# NANO103AE_v1 register map
File version: 1.0
Registers are 32-bit, read-write, reset 0x0 unless marked. A register's access mark holds for its fields unless they carry their own. Offsets are from the block's base; [hi:lo] are bit positions; {n}, {i} and the like mark numbered series.

## RTC — RTC Register Map
Base 0x40008000
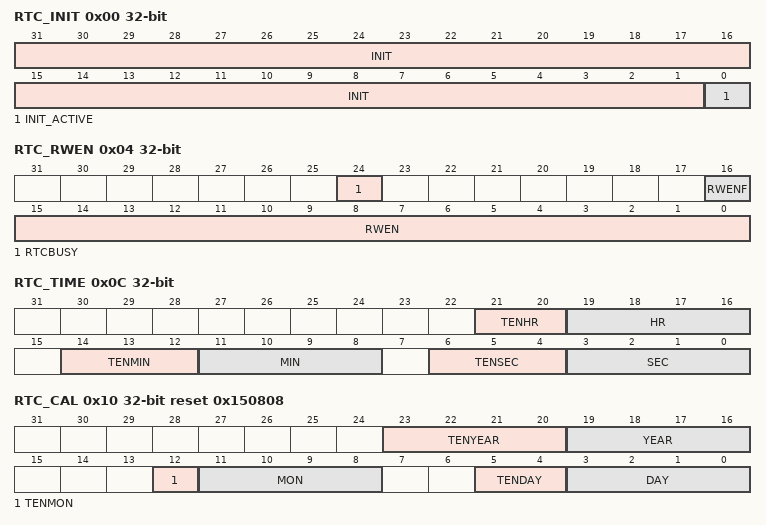
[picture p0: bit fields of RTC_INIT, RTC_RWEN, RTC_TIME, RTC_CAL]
0x00 RTC_INIT — RTC Initiation Register
  [31:1] INIT — RTC Initiation. When RTC block is powered on, RTC is at reset state. User has to write a number (0x a5eb1357) to INIT to make RTC leaving reset state. Once the INIT is written as 0xa5eb1357, the RTC will be in un-reset state permanently. The INIT is a write-only field and read value will be always 0.
  [0] INIT_ACTIVE ro — RTC Active Status (Read Only)
    0=RTC is at reset state; 1=RTC is at normal active state
0x04 RTC_RWEN — RTC Access Enable Register
  [24] RTCBUSY — RTC Write Busy Flag. 0: RTC write access enable. 1: RTC write access disable , RTC under Busy Status. Note: BUSY By Exceed RTC IP Prcessing Write Counter Capacity ( 6 counts Per 1120 PCLK cycles) .
  [16] RWENF ro — RTC Register Access Enable Flag (Read Only)
    0=RTC register read/write Disabled; 1=RTC register read/write Enabled
  [15:0] RWEN wo — RTC Register Access Enable Password (Write Only). Writing 0xA965 to this register will enable RTC access and keep 1024 RTC clock. Writing other vaule will clear RWENF.
0x08 RTC_FREQADJ reset 0x200000 — RTC Frequency Compensation Register
  [21:0] FREQADJ — Frequence Compensation Register. LXT period: the clock period (Hz) of LXT.
0x0C RTC_TIME — RTC Time Loading Register
  [21:20] TENHR — 10-hour Time Digit (0~2). When RTC runs as 12-hour time scale mode, RTC_TIME[21] (the high bit of TENHR[1:0]) means AM/PM indication. (If RTC_TIME[21] is 1, it indicates PM time message.) the high bit of TENHR (RTC_TIME[21]) means AM/PM indication.
  [19:16] HR — 1-Hour Time Digit (0~9)
  [14:12] TENMIN — 10-Min Time Digit (0~5)
  [11:8] MIN — 1-Min Time Digit (0~9)
  [6:4] TENSEC — 10-Sec Time Digit (0~5)
  [3:0] SEC — 1-Sec Time Digit (0~9)
0x10 RTC_CAL reset 0x150808 — RTC Calendar Loading Register
  [23:20] TENYEAR — 10-Year Calendar Digit (0~9)
  [19:16] YEAR — 1-Year Calendar Digit (0~9)
  [12] TENMON — 10-Month Calendar Digit (0~1)
  [11:8] MON — 1-Month Calendar Digit (0~9)
  [5:4] TENDAY — 10-Day Calendar Digit (0~3)
  [3:0] DAY — 1-Day Calendar Digit (0~9)
0x14 RTC_CLKFMT reset 0x1 — RTC Time Scale Selection Register
  [0] _24HEN — 24-hour /12-hour Time Scale Selection. Indicates that RTC_TIME and RTC_TALM are in 24-hour time scale or 12-hour time scale
    0=12-hour time scale with AM and PM indication selected; 1=24-hour time scale selected
0x18 RTC_WEEKDAY reset 0x6 — RTC Day of the Week Register
  [2:0] WEEKDAY — Day of the Week Register
    0=Sunday; 1=Monday; 2=Tuesday; 3=Wednesday; 4=Thursday; 5=Friday; 6=Saturday
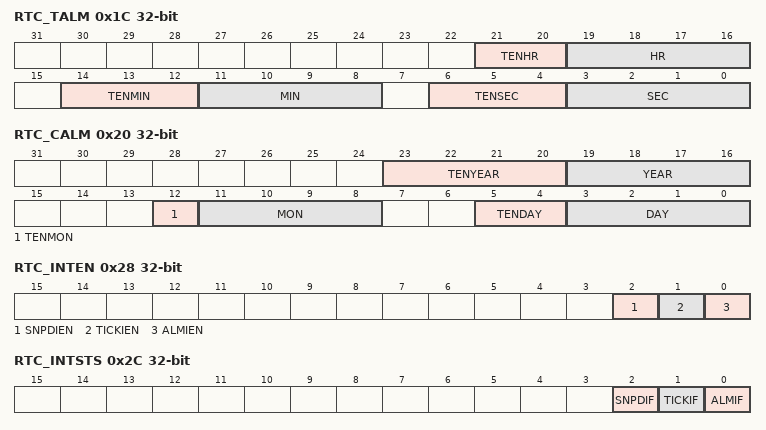
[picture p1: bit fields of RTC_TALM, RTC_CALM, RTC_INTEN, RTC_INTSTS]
0x1C RTC_TALM — RTC Time Alarm Register
  [21:20] TENHR — 10-hour Time Digit of Alarm Setting (0~2). When RTC runs as 12-hour time scale mode, RTC_TIME[21] (the high bit of TENHR[1:0]) means AM/PM indication. (If RTC_TIME[21] is 1, it indicates PM time message.)the high bit of TENHR (RTC_TIME[21]) means AM/PM indication.
  [19:16] HR — 1-Hour Time Digit of Alarm Setting (0~9)
  [14:12] TENMIN — 10-Min Time Digit of Alarm Setting (0~5)
  [11:8] MIN — 1-Min Time Digit of Alarm Setting (0~9)
  [6:4] TENSEC — 10-Sec Time Digit of Alarm Setting (0~5)
  [3:0] SEC — 1-Sec Time Digit of Alarm Setting (0~9)
0x20 RTC_CALM — RTC Calendar Alarm Register
  [23:20] TENYEAR — 10-Year Calendar Digit of Alarm Setting (0~9)
  [19:16] YEAR — 1-Year Calendar Digit of Alarm Setting (0~9)
  [12] TENMON — 10-Month Calendar Digit of Alarm Setting (0~1)
  [11:8] MON — 1-Month Calendar Digit of Alarm Setting (0~9)
  [5:4] TENDAY — 10-Day Calendar Digit of Alarm Setting (0~3)
  [3:0] DAY — 1-Day Calendar Digit of Alarm Setting (0~9)
0x24 RTC_LEAPYEAR ro — RTC Leap Year Indicator Register
  [0] LEAPYEAR — Leap Year Indication Register (Read Only)
    0=This year is not a leap year; 1=This year is leap year
0x28 RTC_INTEN — RTC Interrupt Enable Register
  [2] SNPDIEN — Snoop Detection Interrupt Enable Bit
    0=Snoop detectedinterrupt Disabled; 1=Snoop detected interrupt Enabled
  [1] TICKIEN — Time Tick Interrupt Enable Bit
    0=RTC Time Tick interrupt Disabled; 1=RTC Time Tick interrupt Enabled
  [0] ALMIEN — Alarm Interrupt Enable Bit
    0=RTC Alarm interrupt Disabled; 1=RTC Alarm interrupt Enabled
0x2C RTC_INTSTS — RTC Interrupt Indicator Register
  [2] SNPDIF — Snoop Detect Interrupt Flag. When tamper pin transition event is detected, this bit is set to 1 and an interrupt is generated if Snoop Detection Interrupt enabled SNPDIEN (RTC_INTEN[2]) is set to1. Chip will be waken up from Power-down mode if spare register snooper detect interrupt is enabled. Note:Write 1 to clear this bit.
    0=No snoop event is detected; 1=Snoop event is detected
  [1] TICKIF — RTC Time Tick Interrupt Flag. When RTC time tick happened, this bit will be set to 1 and an interrupt will be generated if RTC Tick Interrupt enabled TICKIEN (RTC_INTEN[1]) is set to 1. Chip will also be waken up if RTC Tick Interrupt is enabled and this bit is set to 1 when chip is running at Power-down mode. Note:Write 1 to clear to clear this bit.
    0=Tick condition does not occur; 1=Tick condition occur
  [0] ALMIF — RTC Alarm Interrupt Flag. When RTC time counters RTC_TIME and RTC_CAL match the alarm setting time registers RTC_TALM and RTC_CALM, this bit will be set to 1 and an interrupt will be generated if RTC Alarm Interrupt enabled ALMIEN (RTC_INTEN[0]) is set to 1. Chip will be waken up if RTC Alarm Interrupt is enabled when chip is at Power-down mode. Note: Write 1 to clear this bit.
    0=Alarm condition is not matched; 1=Alarm condition is matched
0x30 RTC_TICK — RTC Time Tick Register
  [2:0] TICK — Time Tick Register. These bits are used to select RTC time tick period for Periodic Time Tick Interrupt request. Note:This register can be read back after the RTC register access enable bit RWENF (RTC_RWEN[16]) is active.
    0=Time tick is 1 second; 1=Time tick is 1/2 second; 2=Time tick is 1/4 second; 3=Time tick is 1/8 second; 4=Time tick is 1/16 second; 5=Time tick is 1/32 second; 6=Time tick is 1/64 second; 7=Time tick is 1/128 second
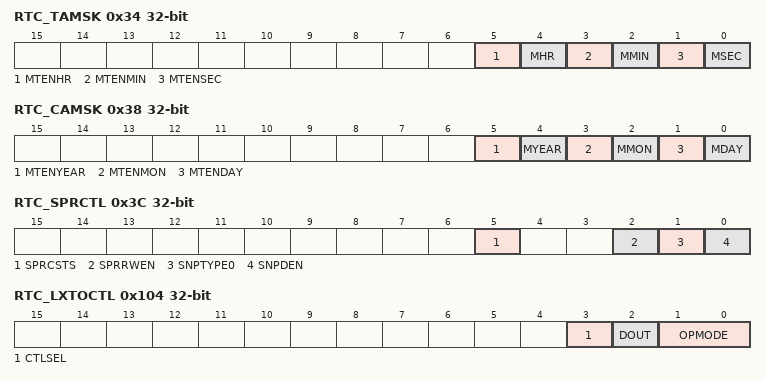
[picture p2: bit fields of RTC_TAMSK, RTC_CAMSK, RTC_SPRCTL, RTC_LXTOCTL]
0x34 RTC_TAMSK — RTC Time Alarm Mask Register
  [5] MTENHR — Mask 10-Hour Time Digit of Alarm Setting (0~2)
  [4] MHR — Mask 1-Hour Time Digit of Alarm Setting (0~9)
  [3] MTENMIN — Mask 10-Min Time Digit of Alarm Setting (0~5)
  [2] MMIN — Mask 1-Min Time Digit of Alarm Setting (0~9)
  [1] MTENSEC — Mask 10-Sec Time Digit of Alarm Setting (0~5)
  [0] MSEC — Mask 1-Sec Time Digit of Alarm Setting (0~9)
0x38 RTC_CAMSK — RTC Calendar Alarm Mask Register
  [5] MTENYEAR — Mask 10-Year Calendar Digit of Alarm Setting (0~9)
  [4] MYEAR — Mask 1-Year Calendar Digit of Alarm Setting (0~9)
  [3] MTENMON — Mask 10-Month Calendar Digit of Alarm Setting (0~1)
  [2] MMON — Mask 1-Month Calendar Digit of Alarm Setting (0~9)
  [1] MTENDAY — Mask 10-Day Calendar Digit of Alarm Setting (0~3)
  [0] MDAY — Mask 1-Day Calendar Digit of Alarm Setting (0~9)
0x3C RTC_SPRCTL — RTC Spare Functional Control Register
  [5] SPRCSTS — SPR Clear Flag. This bit indicates if the RTC_SPR0 ~RTC_SPR4 content is cleared when specify snoop event is detected. Writes 1 to clear this bit.
    0=Spare register content is not cleared; 1=Spare register content is cleared
  [2] SPRRWEN — Spare Register Enable Bit. Note: When spare register is disabled, RTC_SPR0 ~ RTC_SPR4 cannot be accessed. Did not change the content of the spare register, but read data all "0"..
    0=Spare register Disabled; 1=Spare register Enabled
  [1] SNPTYPE0 — Snoop Detection Level. This bit controls TAMPER detect event is rising edge or falling edge.
    0=Rising edge detection; 1=Falling edge detection
  [0] SNPDEN — Snoop Detection Enable Bit
    0=TAMPER pin detection Disabled; 1=TAMPER pin detection Enabled
{0x40+4i} RTC_SPR{i} (i=0..4) — RTC Spare Register {i}
  [31:0] SPARE — Spare Register. This field is used to store back-up information defined by user. This field will be cleared by hardware automatically once a snooper pin event is detected. Before storing back-up information in to RTC_SPRx register, user should write 0xA965 to RTC_RWEN[15:0] to make sure register read/write enable bit REWNF (RTC_RWEN[16]) is enabled.
0x100 RTC_LXTCTL — RTC 32.768 kHz Oscillator Control Register
  [0] LXT_TYPE — LXT TYPE Selection
    0=Crystal type ( Crystal connect to X32KI with X32KO); 1=Oscator illator type ( LXT source from X32KI PIN , X32KO as GPIO
0x104 RTC_LXTOCTL — X32KO Pin Control Register
  [3] CTLSEL — IO Pin State Backup Selection. When low speed 32 kHz oscillator is disabled, X32KO (PF.6) pin can be used as GPIO function. User can program CTLSEL bit to decide X32KO (PF.6) I/O function is controlled by system power domain GPIO module or VBAT power domain RTC_LXTOCTL control register.
    0=X32KO (PF.6) pin I/O function is controlled by GPIO module. It becomes floating when system power is turned off; 1=X32KO (PF.6) pin I/O function is controlled by VBAT power domain, X32KO (PF.6) pin function and I/O status are controlled by OPMODE[1:0] and DOUT after CTLSEL it set to 1. I/O pin keeps the previous state after system power is turned off
  [2] DOUT — IO Output Data
    0=X32KO (PF.6) output low; 1=X32KO (PF.6) output high
  [1:0] OPMODE — GPF0 Operation Mode
    0=X32KO (PF.6) is input only mode, without pull-up resistor; 1=X32KO (PF.6) is output push pull mode; 2=X32KO (PF.6) is open drain mode; 3=X32KO (PF.6) is input only mode with internal pull up
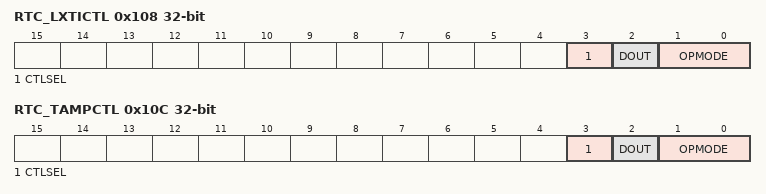
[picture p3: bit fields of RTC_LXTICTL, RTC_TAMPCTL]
0x108 RTC_LXTICTL — X32KI Pin Control Register
  [3] CTLSEL — IO Pin State Backup Selection. When low speed 32 kHz oscillator is disabled, X32KI (PF.7) pin can be used as GPIO function. User can program CTLSEL bit to decide X32KI (PF.7) I/O function is controlled by system power domain GPIO module or VBAT power domain RTC_LXTICTL control register.
    0=X32KI (PF.7) pin I/O function is controlled by GPIO module. It becomes floating state when system power is turned off; 1=X32KI (PF.7) pin I/O function is controlled by VBAT power domain, X32KI (PF.7) pin function and I/O status are controlled by OPMODE[1:0] and DOUT after CTLSEL it set to 1. I/O pin keeps the previous state after system power is turned off
  [2] DOUT — IO Output Data
    0=X32KI (PF.7) output low; 1=X32KI (PF.7) output high
  [1:0] OPMODE — IO Operation Mode
    0=X32KI (PF.7) is input only mode, without pull-up resistor; 1=X32KI (PF.7) is output push pull mode; 2=X32KI (PF.7) is open drain mode; 3=X32KI (PF.7) is input only mode with internal pull up
0x10C RTC_TAMPCTL — TAMPER Pin Control Register
  [3] CTLSEL — IO Pin State Backup Selection. When tamper function is disabled, TAMPER pin can be used as GPIO function. User can program CTLSEL bit to decide (LQFP64:PB.13/LQFP48:PA.9/QFN32:PB.8) I/O function is controlled by system power domain GPIO module or VBAT power domain RTC_TAMPCTL control register.
    0=TAMPER (LQFP64:PB.13/LQFP48:PA.9/QFN32:PB.8) I/O function is controlled by GPIO module. It becomes floating state when system power is turned off; 1=TAMPER (LQFP64:PB.13/LQFP48:PA.9/QFN32:PB.8) I/O function is controlled by VBAT power domain. LQFP64:PB.13/LQFP48:PA.9/QFN32:PB.8 function and I/O status are controlled by OPMODE[1:0] and DOUT after CTLSEL it set to 1. I/O pin state keeps previous state after system power is turned off
  [2] DOUT — IO Output Data
    0=TAMPER (LQFP64:PB.13/LQFP48:PA.9/QFN32:PB.8) output low; 1=TAMPER (LQFP64:PB.13/LQFP48:PA.9/QFN32:PB.8) output high
  [1:0] OPMODE — IO Operation Mode
    0=TAMPER (LQFP64:PB.13/LQFP48:PA.9/QFN32:PB.8) is input only mode, without pull-up resistor; 1=TAMPER (LQFP64:PB.13/LQFP48:PA.9/QFN32:PB.8) is output push pull mode; 2=TAMPER (LQFP64:PB.13/LQFP48:PA.9/QFN32:PB.8) is open drain mode; 3=TAMPER (LQFP64:PB.13/LQFP48:PA.9/QFN32:PB.8) is input only mode with internal pull up
